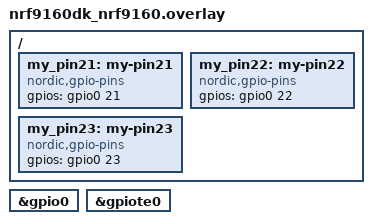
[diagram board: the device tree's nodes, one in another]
// To get started, press Ctrl+Space to bring up the completion menu and view the available nodes.

// You can also use the buttons in the sidebar to perform actions on nodes.
// Actions currently available include:

// * Enabling / disabling the node
// * Adding the bus to a bus
// * Removing the node
// * Connecting ADC channels

// For more help, browse the DeviceTree documentation at https://docs.zephyrproject.org/latest/guides/dts/index.html
// You can also visit the nRF DeviceTree extension documentation at https://docs.nordicsemi.com/bundle/nrf-connect-vscode/page/guides/ncs_configure_app.html#devicetree-support-in-the-extension
/{
    my_pin21: my-pin21{
        compatible = "nordic,gpio-pins";
        gpios = <&gpio0 21 GPIO_ACTIVE_HIGH>;
        status = "okay";
    };
};

/{
    my_pin22: my-pin22{
        compatible = "nordic,gpio-pins";
        gpios = <&gpio0 22 GPIO_ACTIVE_HIGH>;
        status = "okay";
    };
};

/{
    my_pin23: my-pin23{
        compatible = "nordic,gpio-pins";
        gpios = <&gpio0 23 GPIO_ACTIVE_HIGH>;
        status = "okay";
    };
};

&gpio0 {
    status = "okay";
};

&gpiote0 {
    status = "okay";
};

